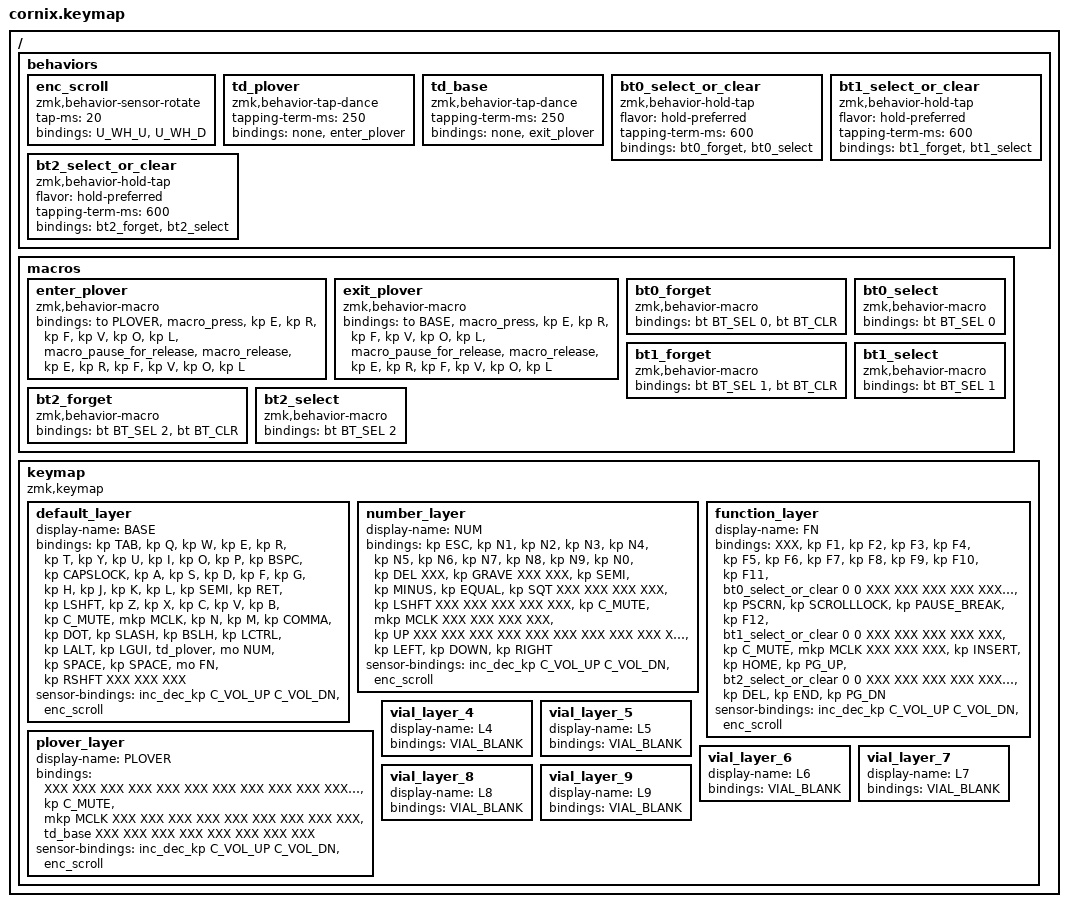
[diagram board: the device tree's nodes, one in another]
/*
 * Converted from Untitled.vil.
 *
 * Vial stores the right half in matrix order (outside-to-inside), while the
 * ZMK physical layout is written left-to-right.  The right-hand rows below
 * are therefore reversed so the physical keys keep their original labels.
 */

#include <behaviors.dtsi>
#include <dt-bindings/zmk/bt.h>
#include <dt-bindings/zmk/keys.h>

#define BASE 0
#define NUM  1
#define FN   2
#define PLOVER 3
#define NAV  1
#define FUN  2

#include "includes/mouse.dtsi"

#define ___ &trans
#define XXX &none

#define VIAL_BLANK \
    XXX XXX XXX XXX XXX XXX XXX XXX XXX XXX XXX XXX \
    XXX XXX XXX XXX XXX XXX XXX XXX XXX XXX XXX XXX \
    XXX XXX XXX XXX XXX XXX &kp C_MUTE &mkp MCLK XXX XXX XXX XXX XXX XXX \
    XXX XXX XXX XXX XXX XXX XXX XXX XXX XXX XXX XXX

/ {
    behaviors {
        /* Vial's second encoder emits mouse-wheel events rather than keycodes. */
        enc_scroll: enc_scroll {
            compatible = "zmk,behavior-sensor-rotate";
            #sensor-binding-cells = <0>;
            /* msc emits its first report after 16 ms; keep each sensor tap alive. */
            tap-ms = <20>;
            bindings = <U_WH_U>, <U_WH_D>;
        };

        /* Require two taps to enter PLOVER and toggle the host Plover app. */
        td_plover: td_plover {
            compatible = "zmk,behavior-tap-dance";
            #binding-cells = <0>;
            tapping-term-ms = <250>;
            bindings = <&none>, <&enter_plover>;
        };

        /* Require two taps to return to BASE and toggle the host Plover app. */
        td_base: td_base {
            compatible = "zmk,behavior-tap-dance";
            #binding-cells = <0>;
            tapping-term-ms = <250>;
            bindings = <&none>, <&exit_plover>;
        };

        /* Select a profile on tap; hold for 600 ms to forget that profile. */
        bt0_select_or_clear: bt0_select_or_clear {
            compatible = "zmk,behavior-hold-tap";
            #binding-cells = <2>;
            flavor = "hold-preferred";
            tapping-term-ms = <600>;
            bindings = <&bt0_forget &bt0_select>;
        };

        bt1_select_or_clear: bt1_select_or_clear {
            compatible = "zmk,behavior-hold-tap";
            #binding-cells = <2>;
            flavor = "hold-preferred";
            tapping-term-ms = <600>;
            bindings = <&bt1_forget &bt1_select>;
        };

        bt2_select_or_clear: bt2_select_or_clear {
            compatible = "zmk,behavior-hold-tap";
            #binding-cells = <2>;
            flavor = "hold-preferred";
            tapping-term-ms = <600>;
            bindings = <&bt2_forget &bt2_select>;
        };
    };

    macros {
        enter_plover: enter_plover {
            compatible = "zmk,behavior-macro";
            #binding-cells = <0>;
            bindings = <&to PLOVER>
                     , <&macro_press &kp E &kp R &kp F &kp V &kp O &kp L>
                     , <&macro_pause_for_release>
                     , <&macro_release &kp E &kp R &kp F &kp V &kp O &kp L>;
        };

        exit_plover: exit_plover {
            compatible = "zmk,behavior-macro";
            #binding-cells = <0>;
            bindings = <&to BASE>
                     , <&macro_press &kp E &kp R &kp F &kp V &kp O &kp L>
                     , <&macro_pause_for_release>
                     , <&macro_release &kp E &kp R &kp F &kp V &kp O &kp L>;
        };

        bt0_forget: bt0_forget {
            compatible = "zmk,behavior-macro";
            #binding-cells = <0>;
            bindings = <&bt BT_SEL 0>, <&bt BT_CLR>;
        };

        bt0_select: bt0_select {
            compatible = "zmk,behavior-macro";
            #binding-cells = <0>;
            bindings = <&bt BT_SEL 0>;
        };

        bt1_forget: bt1_forget {
            compatible = "zmk,behavior-macro";
            #binding-cells = <0>;
            bindings = <&bt BT_SEL 1>, <&bt BT_CLR>;
        };

        bt1_select: bt1_select {
            compatible = "zmk,behavior-macro";
            #binding-cells = <0>;
            bindings = <&bt BT_SEL 1>;
        };

        bt2_forget: bt2_forget {
            compatible = "zmk,behavior-macro";
            #binding-cells = <0>;
            bindings = <&bt BT_SEL 2>, <&bt BT_CLR>;
        };

        bt2_select: bt2_select {
            compatible = "zmk,behavior-macro";
            #binding-cells = <0>;
            bindings = <&bt BT_SEL 2>;
        };
    };

    keymap {
        compatible = "zmk,keymap";

        default_layer {
            display-name = "BASE";
            bindings = <
                // Left row 0 / right row 0
                &kp TAB       &kp Q       &kp W       &kp E       &kp R       &kp T
                &kp Y         &kp U       &kp I       &kp O       &kp P       &kp BSPC

                // Left row 1 / right row 1
                &kp CAPSLOCK  &kp A       &kp S       &kp D       &kp F       &kp G
                &kp H         &kp J       &kp K       &kp L       &kp SEMI     &kp RET

                // Left row 2 / center keys / right row 2
                &kp LSHFT     &kp Z       &kp X       &kp C       &kp V       &kp B
                &kp C_MUTE    &mkp MCLK   &kp N       &kp M       &kp COMMA   &kp DOT
                &kp SLASH     &kp BSLH

                // Left row 3 / right row 3
                &kp LCTRL     &kp LALT    &kp LGUI    &td_plover    &mo NUM      &kp SPACE
                &kp SPACE     &mo FN      &kp RSHFT   XXX          XXX          XXX
            >;
            sensor-bindings = <&inc_dec_kp C_VOL_UP C_VOL_DN
                               &enc_scroll>;
        };

        number_layer {
            display-name = "NUM";
            bindings = <
                // Left row 0 / right row 0
                &kp ESC       &kp N1      &kp N2      &kp N3      &kp N4      &kp N5
                &kp N6        &kp N7      &kp N8      &kp N9      &kp N0      &kp DEL

                // Left row 1 / right row 1
                XXX           &kp GRAVE   XXX         XXX         &kp SEMI    &kp MINUS
                &kp EQUAL     &kp SQT     XXX         XXX         XXX         XXX

                // Left row 2 / center keys / right row 2
                &kp LSHFT     XXX         XXX         XXX         XXX         XXX
                &kp C_MUTE    &mkp MCLK   XXX         XXX         XXX         XXX
                &kp UP        XXX

                // Left row 3 / right row 3
                XXX           XXX         XXX         XXX         XXX         XXX
                XXX           XXX         XXX         &kp LEFT     &kp DOWN     &kp RIGHT
            >;
            sensor-bindings = <&inc_dec_kp C_VOL_UP C_VOL_DN
                               &enc_scroll>;
        };

        function_layer {
            display-name = "FN";
            bindings = <
                // Left row 0 / right row 0
                XXX           &kp F1      &kp F2      &kp F3      &kp F4      &kp F5
                &kp F6        &kp F7      &kp F8      &kp F9      &kp F10     &kp F11

                // Left row 1 / right row 1
                &bt0_select_or_clear 0 0 XXX     XXX         XXX         XXX         XXX
                XXX           XXX         &kp PSCRN   &kp SCROLLLOCK &kp PAUSE_BREAK &kp F12

                // Left row 2 / center keys / right row 2
                &bt1_select_or_clear 0 0 XXX     XXX         XXX         XXX         XXX
                &kp C_MUTE    &mkp MCLK   XXX         XXX         XXX         &kp INSERT
                &kp HOME       &kp PG_UP

                // Left row 3 / right row 3
                &bt2_select_or_clear 0 0 XXX     XXX         XXX         XXX         XXX
                XXX           XXX         XXX         &kp DEL       &kp END      &kp PG_DN
            >;
            sensor-bindings = <&inc_dec_kp C_VOL_UP C_VOL_DN
                               &enc_scroll>;
        };

        plover_layer {
            display-name = "PLOVER";
            bindings = <
                // Left row 0 / right row 0
                XXX           XXX         XXX         XXX         XXX         XXX
                XXX           XXX         XXX         XXX         XXX         XXX

                // Left row 1 / right row 1
                XXX           XXX         XXX         XXX         XXX         XXX
                XXX           XXX         XXX         XXX         XXX         XXX

                // Left row 2 / center keys / right row 2
                XXX           XXX         XXX         XXX         XXX         XXX
                &kp C_MUTE    &mkp MCLK   XXX         XXX         XXX         XXX
                XXX           XXX

                // Left row 3 / right row 3
                XXX           XXX         XXX         &td_base      XXX          XXX
                XXX           XXX         XXX         XXX          XXX          XXX
            >;
            sensor-bindings = <&inc_dec_kp C_VOL_UP C_VOL_DN
                               &enc_scroll>;
        };

        /* Untitled.vil contains six additional layers with only the fixed
         * mute and middle-click positions populated. */
        vial_layer_4 {
            display-name = "L4";
            bindings = <VIAL_BLANK>;
        };

        vial_layer_5 {
            display-name = "L5";
            bindings = <VIAL_BLANK>;
        };

        vial_layer_6 {
            display-name = "L6";
            bindings = <VIAL_BLANK>;
        };

        vial_layer_7 {
            display-name = "L7";
            bindings = <VIAL_BLANK>;
        };

        vial_layer_8 {
            display-name = "L8";
            bindings = <VIAL_BLANK>;
        };

        vial_layer_9 {
            display-name = "L9";
            bindings = <VIAL_BLANK>;
        };
    };
};
